# psoc6_01 register map
Vendor: Cypress Semiconductor; Series: psoc6_01; File version: 1.0
CPU: CM4 r0p1, little endian, MPU, FPU, VTOR, 3 interrupt priority bits
Registers are 32-bit, read-write, reset 0x0 unless marked. A register's access mark holds for its fields unless they carry their own. Offsets are from the block's base; [hi:lo] are bit positions; 'fields as' and 'values as' point back to an identical list.

## CTBM0 — Continuous Time Block Mini
Base 0x41100000
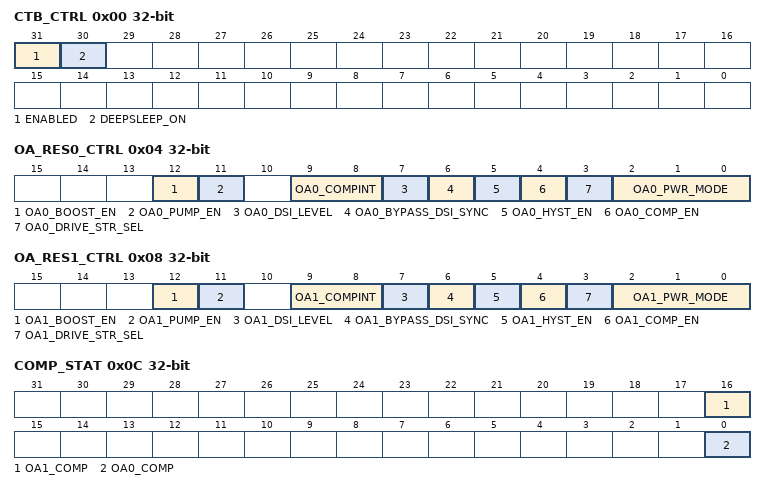
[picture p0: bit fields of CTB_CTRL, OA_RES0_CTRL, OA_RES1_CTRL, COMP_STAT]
0x00 CTB_CTRL — global CTB and power control
  [31] ENABLED — - 0: CTB IP disabled (put analog in power down, open all switches) - 1: CTB IP enabled
  [30] DEEPSLEEP_ON — - 0: CTB IP disabled off during DeepSleep power mode - 1: CTB IP remains enabled during DeepSleep power mode (if ENABLED=1)
0x04 OA_RES0_CTRL — Opamp0 and resistor0 control
  [12] OA0_BOOST_EN — Opamp0 gain booster enable for class A output, for risk mitigation only, not user selectable. Value depends on the drive strength setting - 1x mode: set to 1; 10x mode: set to 0
  [11] OA0_PUMP_EN — Opamp0 pump enable
  [9:8] OA0_COMPINT — Opamp0 comparator edge detect for interrupt and pulse mode of DSI (trigger)
    0=DISABLE (Disabled, no interrupts will be detected); 1=RISING (Rising edge); 2=FALLING (Falling edge); 3=BOTH (Both rising and falling edges)
  [7] OA0_DSI_LEVEL — Opamp0 comparator DSI (trigger) out level : 0=pulse, each time an edge is detected (see OA0_COMPINT) a pulse is sent out on DSI 1=level, DSI output is a synchronized version of the comparator output
  [6] OA0_BYPASS_DSI_SYNC — Opamp0 bypass comparator output synchronization for DSI (trigger) output: 0=synchronize (level or pulse), 1=bypass (output async)
  [5] OA0_HYST_EN — Opamp0 hysteresis enable (10mV)
  [4] OA0_COMP_EN — Opamp0 comparator enable
  [3] OA0_DRIVE_STR_SEL — Opamp0 output strength select 0=1x, 1=10x This setting sets specific requirements for OA0_BOOST_EN and OA0_COMP_TRIM
  [2:0] OA0_PWR_MODE — Opamp0 power level, assumes Cload=15pF for the (internal only) 1x driver or 50pF for the (external) 10x driver
    0=OFF; 1=LOW (Low power mode (IDD: 350uA, GBW: 1MHz for both 1x/10x)); 2=MEDIUM (Medium power mode (IDD: 600uA, GBW: 3MHz for 1x & 2.5MHz for 10x)); 3=HIGH (High power mode for highest GBW (IDD: 1500uA, GBW: 8MHz for 1x & 6MHz for 10x)); 4=RSVD (N/A); 5=PS_LOW (Power Saver Low power mode (IDD: ~20uA with 1uA bias from AREF, GBW: ~100kHz for 1x/10x, offset correcting IDAC is disabled)); 6=PS_MEDIUM (Power Saver Medium power mode (IDD: ~40uA with 1uA bias from AREF, GBW: ~100kHz for 1x/10x, offset correcting IDAC is enabled)); 7=PS_HIGH (Power Saver Medium power mode (IDD: ~60uA with 1uA bias from AREF, GBW: ~200kHz for 1x/10x, offset correcting IDAC is enabled))
0x08 OA_RES1_CTRL — Opamp1 and resistor1 control
  [12] OA1_BOOST_EN — Opamp1 gain booster enable for class A output, for risk mitigation only, not user selectable. Value depends on the drive strength setting - 1x mode: set to 1; 10x mode: set to 0
  [11] OA1_PUMP_EN — Opamp1 pump enable
  [9:8] OA1_COMPINT — Opamp1 comparator edge detect for interrupt and pulse mode of DSI (trigger)
    values as OA_RES0_CTRL.OA0_COMPINT
  [7] OA1_DSI_LEVEL — Opamp1 comparator DSI (trigger) out level : 0=pulse, each time an edge is detected (see OA1_COMPINT) a pulse is sent out on DSI 1=level, DSI output is a synchronized version of the comparator output
  [6] OA1_BYPASS_DSI_SYNC — Opamp1 bypass comparator output synchronization for DSI output: 0=synchronize, 1=bypass
  [5] OA1_HYST_EN — Opamp1 hysteresis enable (10mV)
  [4] OA1_COMP_EN — Opamp1 comparator enable
  [3] OA1_DRIVE_STR_SEL — Opamp1 output strength select 0=1x, 1=10x This setting sets specific requirements for OA1_BOOST_EN and OA1_COMP_TRIM
  [2:0] OA1_PWR_MODE — Opamp1 power level: see description of OA0_PWR_MODE
0x0C COMP_STAT ro — Comparator status
  [16] OA1_COMP — Opamp1 current comparator status
  [0] OA0_COMP — Opamp0 current comparator status
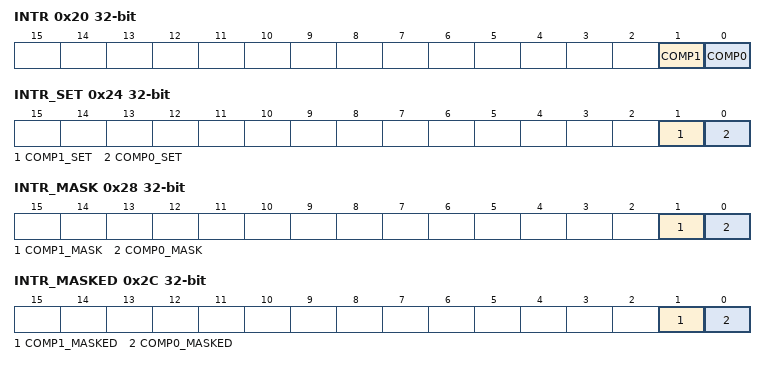
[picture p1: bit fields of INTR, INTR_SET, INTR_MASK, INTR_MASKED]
0x20 INTR — Interrupt request register
  [1] COMP1 — Comparator 1 Interrupt: hardware sets this interrupt when comparator 1 triggers. Write with '1' to clear bit.
  [0] COMP0 — Comparator 0 Interrupt: hardware sets this interrupt when comparator 0 triggers. Write with '1' to clear bit.
0x24 INTR_SET — Interrupt request set register
  [1] COMP1_SET — Write with '1' to set corresponding bit in interrupt request register.
  [0] COMP0_SET — Write with '1' to set corresponding bit in interrupt request register.
0x28 INTR_MASK — Interrupt request mask
  [1] COMP1_MASK — Mask bit for corresponding bit in interrupt request register.
  [0] COMP0_MASK — Mask bit for corresponding bit in interrupt request register.
0x2C INTR_MASKED ro — Interrupt request masked
  [1] COMP1_MASKED — Logical and of corresponding request and mask bits.
  [0] COMP0_MASKED — Logical and of corresponding request and mask bits.
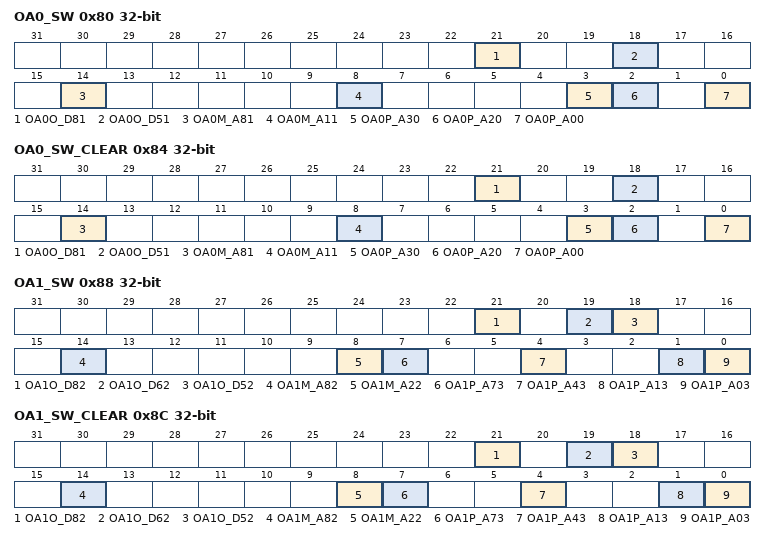
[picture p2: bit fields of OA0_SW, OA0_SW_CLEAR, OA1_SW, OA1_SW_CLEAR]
0x80 OA0_SW — Opamp0 switch control
  [21] OA0O_D81 — Opamp0 output switch to short 1x with 10x drive
  [18] OA0O_D51 — Opamp0 output sarbus0 (ctbbus2 in CTB)
  [14] OA0M_A81 — Opamp0 negative terminal Opamp0 output
  [8] OA0M_A11 — Opamp0 negative terminal P1
  [3] OA0P_A30 — Opamp0 positive terminal ctbbus0
  [2] OA0P_A20 — Opamp0 positive terminal P0
  [0] OA0P_A00 — Opamp0 positive terminal amuxbusa
0x84 OA0_SW_CLEAR — Opamp0 switch control clear
  [21] OA0O_D81 — see corresponding bit in OA0_SW
  [18] OA0O_D51 — see corresponding bit in OA0_SW
  [14] OA0M_A81 — see corresponding bit in OA0_SW
  [8] OA0M_A11 — see corresponding bit in OA0_SW
  [3] OA0P_A30 — see corresponding bit in OA0_SW
  [2] OA0P_A20 — see corresponding bit in OA0_SW
  [0] OA0P_A00 — see corresponding bit in OA0_SW
0x88 OA1_SW — Opamp1 switch control
  [21] OA1O_D82 — Opamp1 output switch to short 1x with 10x drive
  [19] OA1O_D62 — Opamp1 output sarbus1 (ctbbus3 in CTB)
  [18] OA1O_D52 — Opamp1 output sarbus0 (ctbbus2 in CTB)
  [14] OA1M_A82 — Opamp1 negative terminal Opamp1 output
  [8] OA1M_A22 — Opamp1 negative terminal P4
  [7] OA1P_A73 — Opamp1 positive terminal to vref1
  [4] OA1P_A43 — Opamp1 positive terminal ctbbus1
  [1] OA1P_A13 — Opamp1 positive terminal P5
  [0] OA1P_A03 — Opamp1 positive terminal amuxbusb
0x8C OA1_SW_CLEAR — Opamp1 switch control clear
  [21] OA1O_D82 — see corresponding bit in OA1_SW
  [19] OA1O_D62 — see corresponding bit in OA1_SW
  [18] OA1O_D52 — see corresponding bit in OA1_SW
  [14] OA1M_A82 — see corresponding bit in OA1_SW
  [8] OA1M_A22 — see corresponding bit in OA1_SW
  [7] OA1P_A73 — see corresponding bit in OA1_SW
  [4] OA1P_A43 — see corresponding bit in OA1_SW
  [1] OA1P_A13 — see corresponding bit in OA1_SW
  [0] OA1P_A03 — see corresponding bit in OA1_SW
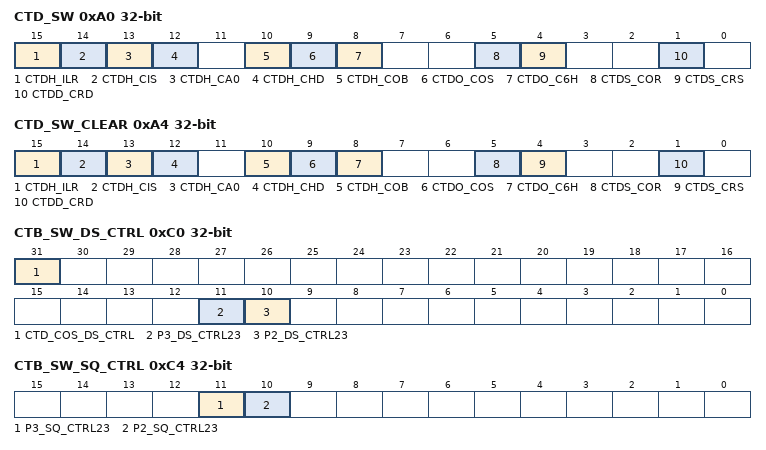
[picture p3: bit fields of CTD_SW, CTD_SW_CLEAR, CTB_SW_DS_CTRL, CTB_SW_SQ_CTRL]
0xA0 CTD_SW — CTDAC connection switch control
  [15] CTDH_ILR — Hold capacitor leakage reduction (drive other side of CIS to capacitor voltage)
  [14] CTDH_CIS — Hold capacitor isolation (from all the other switches)
  [13] CTDH_CA0 — Hold capacitor to opamp input
  [12] CTDH_CHD — Hold capacitor connect
  [10] CTDH_COB — Drive the CTDAC output with CTBM 1x output during hold mode in Sample and Hold operation
  [9] CTDO_COS — ctdvout to Hold capacitor (Sample switch). Note this switch will temporarily be opened for deglitching if CTDAC.DEGLITCH_COS is set
  [8] CTDO_C6H — P6 pin to Hold capacitor
  [5] CTDS_COR — ctdvout to opamp input
  [4] CTDS_CRS — ctdrefsense to opamp input
  [1] CTDD_CRD — CTDAC Reference opamp output to ctdrefdrive
0xA4 CTD_SW_CLEAR — CTDAC connection switch control clear
  [15] CTDH_ILR — see corresponding bit in CTD_SW
  [14] CTDH_CIS — see corresponding bit in CTD_SW
  [13] CTDH_CA0 — see corresponding bit in CTD_SW
  [12] CTDH_CHD — see corresponding bit in CTD_SW
  [10] CTDH_COB — see corresponding bit in CTD_SW
  [9] CTDO_COS — see corresponding bit in CTD_SW
  [8] CTDO_C6H — see corresponding bit in CTD_SW
  [5] CTDS_COR — see corresponding bit in CTD_SW
  [4] CTDS_CRS — see corresponding bit in CTD_SW
  [1] CTDD_CRD — see corresponding bit in CTD_SW
0xC0 CTB_SW_DS_CTRL — CTB bus switch control
  [31] CTD_COS_DS_CTRL — Hold capacitor Sample switch (COS)
  [11] P3_DS_CTRL23 — for P33, D52, D62 (dsi_out[3])
  [10] P2_DS_CTRL23 — for P22, D51 (dsi_out[2])
0xC4 CTB_SW_SQ_CTRL — CTB bus switch Sar Sequencer control
  [11] P3_SQ_CTRL23 — for D52, D62
  [10] P2_SQ_CTRL23 — for D51
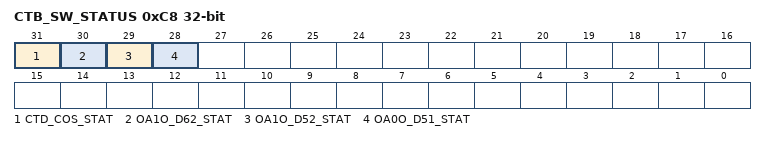
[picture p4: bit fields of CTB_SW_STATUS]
0xC8 CTB_SW_STATUS ro — CTB bus switch control status
  [31] CTD_COS_STAT — see COS bit in CTD_SW
  [30] OA1O_D62_STAT — see OA1O_D62 bit in OA1_SW
  [29] OA1O_D52_STAT — see OA1O_D52 bit in OA1_SW
  [28] OA0O_D51_STAT — see OA0O_D51 bit in OA0_SW
0xF00 OA0_OFFSET_TRIM — Opamp0 trim control
  [5:0] OA0_OFFSET_TRIM — Opamp0 offset trim
0xF04 OA0_SLOPE_OFFSET_TRIM — Opamp0 trim control
  [5:0] OA0_SLOPE_OFFSET_TRIM — Opamp0 slope offset drift trim
0xF08 OA0_COMP_TRIM — Opamp0 trim control
  [1:0] OA0_COMP_TRIM — Opamp0 Compensation Capacitor Trim. Value depends on the drive strength setting - 1x mode: set to 01; 10x mode: set to 11
0xF0C OA1_OFFSET_TRIM — Opamp1 trim control
  [5:0] OA1_OFFSET_TRIM — Opamp1 offset trim
0xF10 OA1_SLOPE_OFFSET_TRIM — Opamp1 trim control
  [5:0] OA1_SLOPE_OFFSET_TRIM — Opamp1 slope offset drift trim
0xF14 OA1_COMP_TRIM — Opamp1 trim control
  [1:0] OA1_COMP_TRIM — Opamp1 Compensation Capacitor Trim. Value depends on the drive strength setting - 1x mode: set to 01; 10x mode: set to 11
